# phy_pma_cmn_registers: IP-XACT component
VLNV cadence:cdns_lib:phy_pma_cmn_registers:1685-2009

## Address spaces and blocks
sd3101_t4_registers.sd3101_phy_registers: base 0x38000, range 0x3ff, width 32

## Registers
Registers are 32-bit, read-write, reset 0x0 unless marked. A register's access mark holds for its fields unless they carry their own. Offsets are from the block's base; lines under a group give offsets from that group; [hi:lo] are bit positions; {n}, {i} and the like mark numbered series; 'fields as' and 'values as' point back to an identical list; <NAME> marks a mode.

## sd3101_t4_registers.sd3101_phy_registers
Base 0x00038000
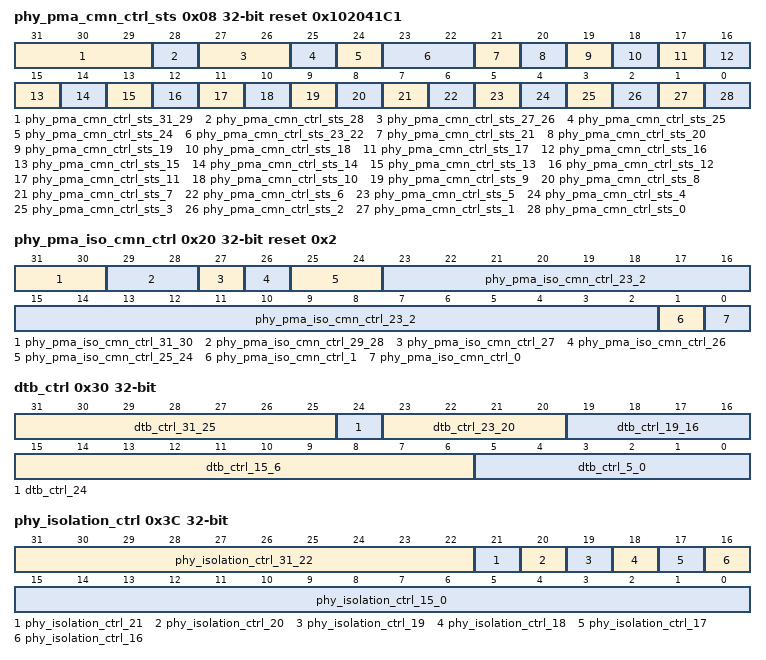
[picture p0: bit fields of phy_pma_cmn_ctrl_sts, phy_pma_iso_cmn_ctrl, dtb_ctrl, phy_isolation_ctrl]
0x08 phy_pma_cmn_ctrl_sts reset 0x102041C1 — PMA common control and status register
  [31:29] phy_pma_cmn_ctrl_sts_31_29 ro — RSVD2
  [28] phy_pma_cmn_ctrl_sts_28 write-1-sets — CMN_RDY_MASK
  [27:26] phy_pma_cmn_ctrl_sts_27_26 ro — RSVD1
  [25] phy_pma_cmn_ctrl_sts_25 write-1-sets — RCVR_OUT_EN1
  [24] phy_pma_cmn_ctrl_sts_24 write-1-sets — RCVR_OUT_EN0
  [23:22] phy_pma_cmn_ctrl_sts_23_22 ro — RSVD0
  [21] phy_pma_cmn_ctrl_sts_21 ro — PWRGD_AVDD
  [20] phy_pma_cmn_ctrl_sts_20 ro — CMN_SUSP_ACK
  [19] phy_pma_cmn_ctrl_sts_19 write-1-sets — CMN_SUSP_REQ
  [18] phy_pma_cmn_ctrl_sts_18 ro — REFCLK_ACT
  [17] phy_pma_cmn_ctrl_sts_17 write-1-sets — REFCLK_DIS
  [16] phy_pma_cmn_ctrl_sts_16 ro — CMN_RDY
  [15] phy_pma_cmn_ctrl_sts_15 write-1-sets — PLL1_RST
  [14] phy_pma_cmn_ctrl_sts_14 ro — PLL1_DIS
  [13] phy_pma_cmn_ctrl_sts_13 ro — PLL1_SUSP_ACK
  [12] phy_pma_cmn_ctrl_sts_12 write-1-sets — PLL1_SUSP_REQ
  [11] phy_pma_cmn_ctrl_sts_11 ro — PLL1_RDY
  [10] phy_pma_cmn_ctrl_sts_10 ro — PLL1_LOCK
  [9] phy_pma_cmn_ctrl_sts_9 write-1-sets — PLL1_MODE
  [8] phy_pma_cmn_ctrl_sts_8 write-1-sets — PLL1_EN
  [7] phy_pma_cmn_ctrl_sts_7 write-1-sets — PLL0_RST
  [6] phy_pma_cmn_ctrl_sts_6 ro — PLL0_DIS
  [5] phy_pma_cmn_ctrl_sts_5 ro — PLL0_SUSP_ACK
  [4] phy_pma_cmn_ctrl_sts_4 write-1-sets — PLL0_SUSP_REQ
  [3] phy_pma_cmn_ctrl_sts_3 ro — PLL0_RDY
  [2] phy_pma_cmn_ctrl_sts_2 ro — PLL0_LOCK
  [1] phy_pma_cmn_ctrl_sts_1 write-1-sets — PLL0_MODE
  [0] phy_pma_cmn_ctrl_sts_0 write-1-sets — PLL0_EN
0x0C phy_pma_cmn_ctrl_sts_clr reset 0x102041C1 — PMA common control and status clear register
  [31:0] phy_pma_cmn_ctrl_sts_clr_31_0 write-1-clears — CLR
0x10 uc_top_scrpad8 — PHY top uController scratchpad/mailbox 8 register
  [31:0] uc_top_scrpad8_31_0 — VALUE
0x14 uc_top_scrpad9 — PHY top uController scratchpad/mailbox 9 register
  [31:0] uc_top_scrpad9_31_0 — VALUE
0x18 uc_top_scrpad10 — PHY top uController scratchpad/mailbox 10 register
  [31:0] uc_top_scrpad10_31_0 — VALUE
0x1C uc_top_scrpad11 — PHY top uController scratchpad/mailbox 11 register
  [31:0] uc_top_scrpad11_31_0 — VALUE
0x20 phy_pma_iso_cmn_ctrl reset 0x2 — PMA common control signal isolation register
  [31:30] phy_pma_iso_cmn_ctrl_31_30 — PLL_SEL1
  [29:28] phy_pma_iso_cmn_ctrl_29_28 — PLL_SEL0
  [27] phy_pma_iso_cmn_ctrl_27 ro — RSVD
  [26] phy_pma_iso_cmn_ctrl_26 — DIG_SEL
  [25:24] phy_pma_iso_cmn_ctrl_25_24 — DIG_DIV
  [23:2] phy_pma_iso_cmn_ctrl_23_2 ro — RSVD
  [1] phy_pma_iso_cmn_ctrl_1 — POW_MASK_ALL
  [0] phy_pma_iso_cmn_ctrl_0 — CMN_RST
0x30 dtb_ctrl — Digital test bus control register
  [31:25] dtb_ctrl_31_25 ro — RSVD1
  [24] dtb_ctrl_24 — DTB_CLK_EN
  [23:20] dtb_ctrl_23_20 — DTB_CLK_LN_- SEL
  [19:16] dtb_ctrl_19_16 — DTB_CLK_SEL
  [15:6] dtb_ctrl_15_6 ro — RSVD0
  [5:0] dtb_ctrl_5_0 — DTB_SEL
0x34 dtb_data reset 0x54500 — Digital test bus data register
  [31:0] dtb_data_31_0 ro — DTB_DATA
0x3C phy_isolation_ctrl — PHY isolation control register
  [31:22] phy_isolation_ctrl_31_22 ro — RSVD
  [21] phy_isolation_ctrl_21 — ISO_CLK_OVR
  [20] phy_isolation_ctrl_20 — MB_BYP_EN
  [19] phy_isolation_ctrl_19 — ISO_MD_EN
  [18] phy_isolation_ctrl_18 — CMN_ISO_EN
  [17] phy_isolation_ctrl_17 — ISO_TX_OVR
  [16] phy_isolation_ctrl_16 — ISO_MD_SEL
  [15:0] phy_isolation_ctrl_15_0 — LN_ISO_EN
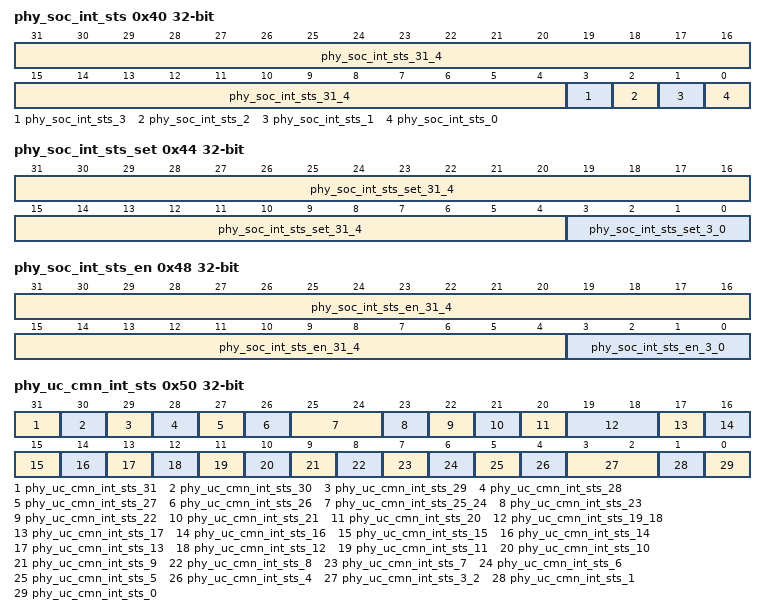
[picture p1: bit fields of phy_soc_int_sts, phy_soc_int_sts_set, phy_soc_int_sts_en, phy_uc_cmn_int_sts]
0x40 phy_soc_int_sts — PHY SoC interrupt status register
  [31:4] phy_soc_int_sts_31_4 ro — RSVD
  [3] phy_soc_int_sts_3 write-1-clears — CORR_ERR
  [2] phy_soc_int_sts_2 write-1-clears — UNCORR_ERR
  [1] phy_soc_int_sts_1 write-1-clears — TOP_SOC_API
  [0] phy_soc_int_sts_0 write-1-clears — WTCHDG_FIRE
0x44 phy_soc_int_sts_set — PHY SoC interrupt status set register
  [31:4] phy_soc_int_sts_set_31_4 ro — RSVD
  [3:0] phy_soc_int_sts_set_3_0 write-1-sets — SET
0x48 phy_soc_int_sts_en — PHY SoC interrupt status enable register
  [31:4] phy_soc_int_sts_en_31_4 ro — RSVD
  [3:0] phy_soc_int_sts_en_3_0 — ENABLE
0x50 phy_uc_cmn_int_sts — PHY top uC common interrupt status register
  [31] phy_uc_cmn_int_sts_31 ro — LN_INT
  [30] phy_uc_cmn_int_sts_30 write-1-clears — SOC_TOP_API
  [29] phy_uc_cmn_int_sts_29 write-1-clears — WCHDG_MID
  [28] phy_uc_cmn_int_sts_28 write-1-clears — RSVD6
  [27] phy_uc_cmn_int_sts_27 write-1-clears — RST_FALL
  [26] phy_uc_cmn_int_sts_26 write-1-clears — RST_RISE
  [25:24] phy_uc_cmn_int_sts_25_24 write-1-clears — RSVD5
  [23] phy_uc_cmn_int_sts_23 write-1-clears — PLL1_DSBL_RISE
  [22] phy_uc_cmn_int_sts_22 write-1-clears — PLL1_SPND_RISE
  [21] phy_uc_cmn_int_sts_21 write-1-clears — RSVD4
  [20] phy_uc_cmn_int_sts_20 write-1-clears — PLL1_RDY_RISE
  [19:18] phy_uc_cmn_int_sts_19_18 write-1-clears — RSVD3
  [17] phy_uc_cmn_int_sts_17 write-1-clears — PLL0_DSBL_RISE
  [16] phy_uc_cmn_int_sts_16 write-1-clears — PLL0_SPND_RISE
  [15] phy_uc_cmn_int_sts_15 write-1-clears — RSVD2
  [14] phy_uc_cmn_int_sts_14 write-1-clears — PLL0_RDY_RISE
  [13] phy_uc_cmn_int_sts_13 write-1-clears — PIPE4_RST_FALL
  [12] phy_uc_cmn_int_sts_12 write-1-clears — PIPE4_RST_RISE
  [11] phy_uc_cmn_int_sts_11 write-1-clears — PIPE7_RST_FALL
  [10] phy_uc_cmn_int_sts_10 write-1-clears — PIPE7_RST_RISE
  [9] phy_uc_cmn_int_sts_9 write-1-clears — DP_RST_FALL
  [8] phy_uc_cmn_int_sts_8 write-1-clears — DP_RST_RISE
  [7] phy_uc_cmn_int_sts_7 write-1-clears — PLL_EN_FALL
  [6] phy_uc_cmn_int_sts_6 write-1-clears — PLL_EN_RISE
  [5] phy_uc_cmn_int_sts_5 write-1-clears — SPND_ACK_FALL
  [4] phy_uc_cmn_int_sts_4 write-1-clears — SPND_ACK_RISE
  [3:2] phy_uc_cmn_int_sts_3_2 write-1-clears — RSVD0
  [1] phy_uc_cmn_int_sts_1 write-1-clears — CMNRDY_FALL
  [0] phy_uc_cmn_int_sts_0 write-1-clears — CMNRDY_RISE
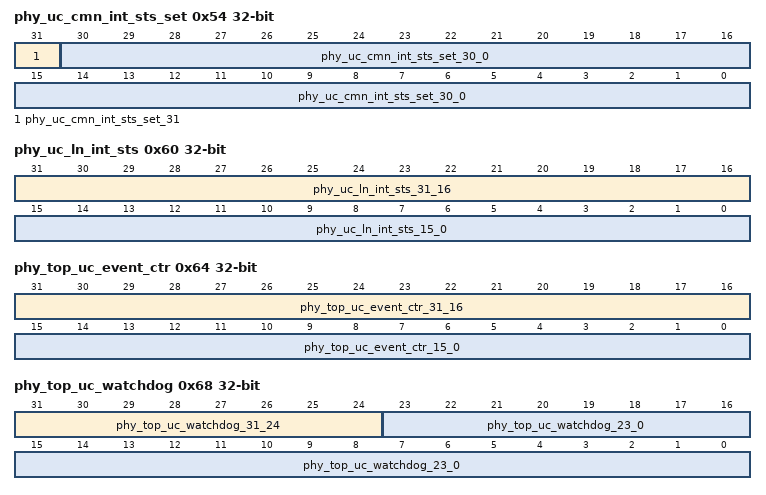
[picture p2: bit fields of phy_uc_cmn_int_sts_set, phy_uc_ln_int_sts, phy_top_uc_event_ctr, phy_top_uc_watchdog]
0x54 phy_uc_cmn_int_sts_set — PHY top uController common interrupt status set register
  [31] phy_uc_cmn_int_sts_set_31 ro — RSVD
  [30:0] phy_uc_cmn_int_sts_set_30_0 write-1-sets — SET
0x58 phy_uc_cmn_en_int_sts — PHY top uController common enabled interrupt status register
  [31:0] phy_uc_cmn_en_int_sts_31_0 ro — ENABLED_INT
0x5C phy_uc_cmn_int_sts_en — PHY top uController common interrupt status enable register
  [31:0] phy_uc_cmn_int_sts_en_31_0 — ENABLE
0x60 phy_uc_ln_int_sts — PHY top uController lane interrupt status register
  [31:16] phy_uc_ln_int_sts_31_16 ro — LN_PMA_INT
  [15:0] phy_uc_ln_int_sts_15_0 ro — LN_PCS_INT
0x64 phy_top_uc_event_ctr — PHY top uC event counter register
  [31:16] phy_top_uc_event_ctr_31_16 ro — RSVD
  [15:0] phy_top_uc_event_ctr_15_0 ro — EVENT_CNT
0x68 phy_top_uc_watchdog
  [31:24] phy_top_uc_watchdog_31_24 ro — RSVD
  [23:0] phy_top_uc_watchdog_23_0 ro — WATCHDOG
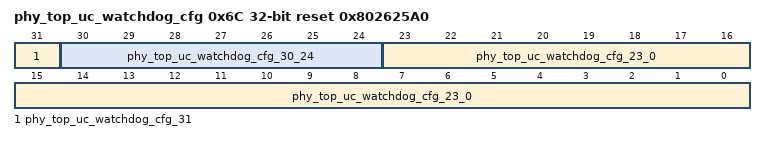
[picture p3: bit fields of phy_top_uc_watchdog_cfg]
0x6C phy_top_uc_watchdog_cfg reset 0x802625A0 — PHY top uC watchdog configuration register
  [31] phy_top_uc_watchdog_cfg_31 ro — STATUS
  [30:24] phy_top_uc_watchdog_cfg_30_24 ro — RSVD
  [23:0] phy_top_uc_watchdog_cfg_23_0 — START_VAL
{0x40+4i} uc_top_scrpad{i} (i=12..14) — PHY top uController scratchpad/mailbox {i} register
  [31:0] uc_top_scrpad{i}_31_0 — VALUE
